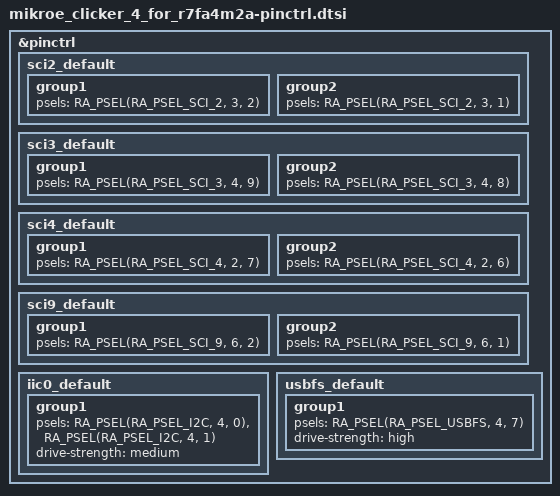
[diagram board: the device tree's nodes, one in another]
/*
 * Copyright (c) 2026 Ian Morris
 *
 * SPDX-License-Identifier: Apache-2.0
 */

&pinctrl {
	// sci0_default: sci0_default {
	// 	group1 {
	// 		/* MISO MOSI RSPCK */
	// 		psels = <RA_PSEL(RA_PSEL_SCI_0, 4, 10)>,
	// 			<RA_PSEL(RA_PSEL_SCI_0, 4, 11)>,
	// 			<RA_PSEL(RA_PSEL_SCI_0, 4, 12)>,
	// 	};
	// };

	sci2_default: sci2_default {
		group1 {
			/* tx */
			psels = <RA_PSEL(RA_PSEL_SCI_2, 3, 2)>;
		};

		group2 {
			/* rx */
			psels = <RA_PSEL(RA_PSEL_SCI_2, 3, 1)>;
		};
	};

	sci3_default: sci3_default {
		group1 {
			/* tx */
			psels = <RA_PSEL(RA_PSEL_SCI_3, 4, 9)>;
		};

		group2 {
			/* rx */
			psels = <RA_PSEL(RA_PSEL_SCI_3, 4, 8)>;
		};
	};

	sci4_default: sci4_default {
		group1 {
			/* tx */
			psels = <RA_PSEL(RA_PSEL_SCI_4, 2, 7)>;
		};

		group2 {
			/* rx */
			psels = <RA_PSEL(RA_PSEL_SCI_4, 2, 6)>;
		};
	};

	sci9_default: sci9_default {
		group1 {
			/* tx */
			psels = <RA_PSEL(RA_PSEL_SCI_9, 6, 2)>;
		};

		group2 {
			/* rx */
			psels = <RA_PSEL(RA_PSEL_SCI_9, 6, 1)>;
		};
	};

	iic0_default: iic0_default {
		group1 {
			/* SCL0 SDA0 */
			psels = <RA_PSEL(RA_PSEL_I2C, 4, 0)>,
				<RA_PSEL(RA_PSEL_I2C, 4, 1)>;
			drive-strength = "medium";
		};
	};

	usbfs_default: usbfs_default {
		group1 {
			/* USB_VBUS */
			psels = <RA_PSEL(RA_PSEL_USBFS, 4, 7)>;
			drive-strength = "high";
		};
	};
};
